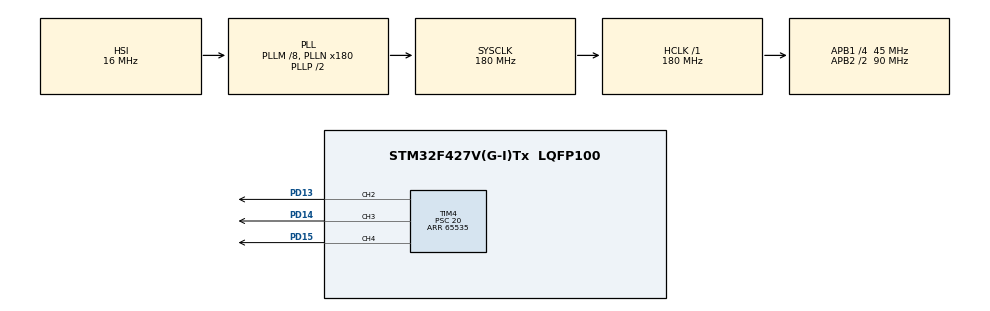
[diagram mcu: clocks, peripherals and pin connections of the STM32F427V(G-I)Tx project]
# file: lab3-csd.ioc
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Mcu.Family=STM32F4
Mcu.Name=STM32F427V(G-I)Tx
Mcu.Package=LQFP100
NVIC.PriorityGroup=NVIC_PRIORITYGROUP_4
NVIC.TIM6_DAC_IRQn=true\:0\:0\:false\:false\:true\:true\:true\:true
NVIC.TIM7_IRQn=true\:0\:0\:false\:false\:true\:true\:true\:true
PA13.Mode=JTAG_5_pins
PA13.Signal=SYS_JTMS-SWDIO
PA14.Mode=JTAG_5_pins
PA14.Signal=SYS_JTCK-SWCLK
PA15.Mode=JTAG_5_pins
PA15.Signal=SYS_JTDI
PB3.Mode=JTAG_5_pins
PB3.Signal=SYS_JTDO-SWO
PB4.Mode=JTAG_5_pins
PB4.Signal=SYS_JTRST
PD13.Signal=S_TIM4_CH2
PD14.Signal=S_TIM4_CH3
PD15.Signal=S_TIM4_CH4
ProjectManager.HeapSize=0x200
ProjectManager.StackSize=0x400
ProjectManager.TargetToolchain=STM32CubeIDE
RCC.48MHZClocksFreq_Value=90000000
RCC.AHBFreq_Value=180000000
RCC.APB1CLKDivider=RCC_HCLK_DIV4
RCC.APB1Freq_Value=45000000
RCC.APB1TimFreq_Value=90000000
RCC.APB2CLKDivider=RCC_HCLK_DIV2
RCC.APB2Freq_Value=90000000
RCC.APB2TimFreq_Value=180000000
RCC.CortexFreq_Value=180000000
RCC.HCLKFreq_Value=180000000
RCC.HSE_VALUE=25000000
RCC.HSI_VALUE=16000000
RCC.LSE_VALUE=32768
RCC.PLLM=8
RCC.PLLN=180
RCC.SYSCLKFreq_VALUE=180000000
RCC.SYSCLKSource=RCC_SYSCLKSOURCE_PLLCLK
RCC.VCOOutputFreq_Value=360000000
SH.S_TIM4_CH2.0=TIM4_CH2,PWM Generation2 CH2
SH.S_TIM4_CH3.0=TIM4_CH3,PWM Generation3 CH3
SH.S_TIM4_CH4.0=TIM4_CH4,PWM Generation4 CH4
TIM4.Channel-PWM\ Generation2\ CH2=TIM_CHANNEL_2
TIM4.Channel-PWM\ Generation3\ CH3=TIM_CHANNEL_3
TIM4.Channel-PWM\ Generation4\ CH4=TIM_CHANNEL_4
TIM4.Period=65535
TIM4.Prescaler=20
TIM4.Pulse-PWM\ Generation2\ CH2=500
TIM6.Period=65535
TIM6.Prescaler=8999
TIM7.Period=65535
TIM7.Prescaler=8999
VP_TIM4_VS_ClockSourceINT.Mode=Internal
VP_TIM6_VS_ClockSourceINT.Mode=Enable_Timer
VP_TIM7_VS_ClockSourceINT.Mode=Enable_Timer
board=custom

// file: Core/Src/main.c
/* USER CODE BEGIN Header */
/**
  ******************************************************************************
  * @file           : main.c
  * @brief          : Main program body
  ******************************************************************************
  * @attention
  *
  * Copyright (c) 2025 STMicroelectronics.
  * All rights reserved.
  *
  * This software is licensed under terms that can be found in the LICENSE file
  * in the root directory of this software component.
  * If no LICENSE file comes with this software, it is provided AS-IS.
  *
  ******************************************************************************
  */
/* USER CODE END Header */
#include "main.h"

TIM_HandleTypeDef htim4;
TIM_HandleTypeDef htim6;
TIM_HandleTypeDef htim7;

void SystemClock_Config(void);
static void MX_GPIO_Init(void);
static void MX_TIM4_Init(void);
static void MX_TIM6_Init(void);
static void MX_TIM7_Init(void);

/* USER CODE BEGIN 0 */

#define MAX_PHASE 10
#define GREEN 2
#define ORANGE 3
#define RED 4
#define MAX_BRIGHT 65536
#define MIN_BRIGHT 0
#define GREEN_TIMER &htim6
#define RED_ORANGE_TIMER &htim7
int start_timer_gr_val = 0;
int start_timer_ro_val = 0;
int max_green = MAX_BRIGHT;
int max_ro = MAX_BRIGHT;
int is_up_green_global = -1;
int is_up_ro_global = -1;

void change_speed(TIM_HandleTypeDef *timer, int speed) {
	__HAL_TIM_SET_PRESCALER(timer, speed);
}

int light_green(int speed, int max_brightness, int min_brightness, int is_up) {
	if(is_up_green_global == -1) is_up_green_global = is_up;
	change_speed(GREEN_TIMER, speed);
	int cur_ticks = __HAL_TIM_GET_COUNTER(GREEN_TIMER);
	int up_brightness = (cur_ticks > min_brightness ? (cur_ticks < max_brightness ? cur_ticks : max_brightness) : min_brightness);
	int less_brightness = (max_brightness-cur_ticks > min_brightness ? (max_brightness-cur_ticks) : min_brightness);
	int cur_brightness = is_up == 1 ? up_brightness : less_brightness;

	TIM4->CCR2=cur_brightness;

	if(is_up_green_global != is_up) {
		is_up_green_global = is_up;
		__HAL_TIM_SET_COUNTER(GREEN_TIMER, cur_ticks >= max_green ? min_brightness : cur_ticks);
	}

	max_green = max_brightness;
	return cur_ticks >= max_green ? 1 : 0;
}

int light_orange_red(int speed, int color, int max_brightness, int min_brightness, int is_up) {
	if(is_up_ro_global == -1) is_up_ro_global = is_up;
	change_speed(RED_ORANGE_TIMER, speed);
	int cur_ticks = __HAL_TIM_GET_COUNTER(RED_ORANGE_TIMER);
	int cur_brightness = is_up == 1 ? cur_ticks : MAX_BRIGHT - cur_ticks;

	if(color == ORANGE) TIM4->CCR3=cur_brightness;
	else if(color == RED) TIM4->CCR4=cur_brightness;

	if(is_up_ro_global != is_up) {
		is_up_ro_global = is_up;
		__HAL_TIM_SET_COUNTER(RED_ORANGE_TIMER, cur_ticks >= max_ro ? min_brightness : cur_ticks);
	}

	max_ro = max_brightness;
	return cur_ticks >= max_ro ? 1 : 0;
}

int light(int speed, int color, int min_brightness, int max_brightness, int is_up) {
	if(max_brightness > MAX_BRIGHT) max_brightness = MAX_BRIGHT;
	if(min_brightness < MIN_BRIGHT) min_brightness = MIN_BRIGHT;
	if(color == GREEN) return light_green(speed, max_brightness, min_brightness, is_up);
	else return light_orange_red(speed, color, max_brightness, min_brightness, is_up);
}

void HAL_TIM_PeriodElapsedCallback(TIM_HandleTypeDef *htim)
{
	if( htim->Instance == TIM6 ){
		__HAL_TIM_SET_COUNTER(GREEN_TIMER, max_green);
	}
	if( htim->Instance == TIM7 ){
		__HAL_TIM_SET_COUNTER(RED_ORANGE_TIMER, max_ro);
	}
}

/* USER CODE END 0 */

int main(void)
{

  /* MCU Configuration--------------------------------------------------------*/

  /* Reset of all peripherals, Initializes the Flash interface and the Systick. */
  HAL_Init();

  /* Configure the system clock */
  SystemClock_Config();

  /* Initialize all configured peripherals */
  MX_GPIO_Init();
  MX_TIM4_Init();
  MX_TIM6_Init();
  MX_TIM7_Init();

  /* Infinite loop */
  /* USER CODE BEGIN WHILE */
  HAL_TIM_Base_Start_IT(&htim6);
  HAL_TIM_Base_Start_IT(&htim7);
  HAL_TIM_PWM_Start(&htim4, TIM_CHANNEL_2);
  HAL_TIM_PWM_Start(&htim4, TIM_CHANNEL_3);
  HAL_TIM_PWM_Start(&htim4, TIM_CHANNEL_4);

  int up = 0;
  while (1)
  {
	  if(light(1000, RED, 0, 65535, up) == 1) {
		  up = 1;
	  }
//	  light(1000, GREEN, 0, 65535, 0);
    /* USER CODE END WHILE */

  }
}

void SystemClock_Config(void)
{
  RCC_OscInitTypeDef RCC_OscInitStruct = {0};
  RCC_ClkInitTypeDef RCC_ClkInitStruct = {0};

  /** Configure the main internal regulator output voltage
  */
  __HAL_RCC_PWR_CLK_ENABLE();
  __HAL_PWR_VOLTAGESCALING_CONFIG(PWR_REGULATOR_VOLTAGE_SCALE1);

  /** Initializes the RCC Oscillators according to the specified parameters
  * in the RCC_OscInitTypeDef structure.
  */
  RCC_OscInitStruct.OscillatorType = RCC_OSCILLATORTYPE_HSI;
  RCC_OscInitStruct.HSIState = RCC_HSI_ON;
  RCC_OscInitStruct.HSICalibrationValue = RCC_HSICALIBRATION_DEFAULT;
  RCC_OscInitStruct.PLL.PLLState = RCC_PLL_ON;
  RCC_OscInitStruct.PLL.PLLSource = RCC_PLLSOURCE_HSI;
  RCC_OscInitStruct.PLL.PLLM = 8;
  RCC_OscInitStruct.PLL.PLLN = 180;
  RCC_OscInitStruct.PLL.PLLP = RCC_PLLP_DIV2;
  RCC_OscInitStruct.PLL.PLLQ = 4;
  if (HAL_RCC_OscConfig(&RCC_OscInitStruct) != HAL_OK)
  {
    Error_Handler();
  }

  /** Activate the Over-Drive mode
  */
  if (HAL_PWREx_EnableOverDrive() != HAL_OK)
  {
    Error_Handler();
  }

  /** Initializes the CPU, AHB and APB buses clocks
  */
  RCC_ClkInitStruct.ClockType = RCC_CLOCKTYPE_HCLK|RCC_CLOCKTYPE_SYSCLK
                              |RCC_CLOCKTYPE_PCLK1|RCC_CLOCKTYPE_PCLK2;
  RCC_ClkInitStruct.SYSCLKSource = RCC_SYSCLKSOURCE_PLLCLK;
  RCC_ClkInitStruct.AHBCLKDivider = RCC_SYSCLK_DIV1;
  RCC_ClkInitStruct.APB1CLKDivider = RCC_HCLK_DIV4;
  RCC_ClkInitStruct.APB2CLKDivider = RCC_HCLK_DIV2;

  if (HAL_RCC_ClockConfig(&RCC_ClkInitStruct, FLASH_LATENCY_5) != HAL_OK)
  {
    Error_Handler();
  }
}

static void MX_TIM4_Init(void)
{

  TIM_ClockConfigTypeDef sClockSourceConfig = {0};
  TIM_MasterConfigTypeDef sMasterConfig = {0};
  TIM_OC_InitTypeDef sConfigOC = {0};

  htim4.Instance = TIM4;
  htim4.Init.Prescaler = 20;
  htim4.Init.CounterMode = TIM_COUNTERMODE_UP;
  htim4.Init.Period = 65535;
  htim4.Init.ClockDivision = TIM_CLOCKDIVISION_DIV1;
  htim4.Init.AutoReloadPreload = TIM_AUTORELOAD_PRELOAD_DISABLE;
  if (HAL_TIM_Base_Init(&htim4) != HAL_OK)
  {
    Error_Handler();
  }
  sClockSourceConfig.ClockSource = TIM_CLOCKSOURCE_INTERNAL;
  if (HAL_TIM_ConfigClockSource(&htim4, &sClockSourceConfig) != HAL_OK)
  {
    Error_Handler();
  }
  if (HAL_TIM_PWM_Init(&htim4) != HAL_OK)
  {
    Error_Handler();
  }
  sMasterConfig.MasterOutputTrigger = TIM_TRGO_RESET;
  sMasterConfig.MasterSlaveMode = TIM_MASTERSLAVEMODE_DISABLE;
  if (HAL_TIMEx_MasterConfigSynchronization(&htim4, &sMasterConfig) != HAL_OK)
  {
    Error_Handler();
  }
  sConfigOC.OCMode = TIM_OCMODE_PWM1;
  sConfigOC.Pulse = 500;
  sConfigOC.OCPolarity = TIM_OCPOLARITY_HIGH;
  sConfigOC.OCFastMode = TIM_OCFAST_DISABLE;
  if (HAL_TIM_PWM_ConfigChannel(&htim4, &sConfigOC, TIM_CHANNEL_2) != HAL_OK)
  {
    Error_Handler();
  }
  sConfigOC.Pulse = 0;
  if (HAL_TIM_PWM_ConfigChannel(&htim4, &sConfigOC, TIM_CHANNEL_3) != HAL_OK)
  {
    Error_Handler();
  }
  if (HAL_TIM_PWM_ConfigChannel(&htim4, &sConfigOC, TIM_CHANNEL_4) != HAL_OK)
  {
    Error_Handler();
  }
  HAL_TIM_MspPostInit(&htim4);

}

static void MX_TIM6_Init(void)
{

  TIM_MasterConfigTypeDef sMasterConfig = {0};

  htim6.Instance = TIM6;
  htim6.Init.Prescaler = 8999;
  htim6.Init.CounterMode = TIM_COUNTERMODE_UP;
  htim6.Init.Period = 65535;
  htim6.Init.AutoReloadPreload = TIM_AUTORELOAD_PRELOAD_DISABLE;
  if (HAL_TIM_Base_Init(&htim6) != HAL_OK)
  {
    Error_Handler();
  }
  sMasterConfig.MasterOutputTrigger = TIM_TRGO_RESET;
  sMasterConfig.MasterSlaveMode = TIM_MASTERSLAVEMODE_DISABLE;
  if (HAL_TIMEx_MasterConfigSynchronization(&htim6, &sMasterConfig) != HAL_OK)
  {
    Error_Handler();
  }

}

static void MX_TIM7_Init(void)
{

  TIM_MasterConfigTypeDef sMasterConfig = {0};

  htim7.Instance = TIM7;
  htim7.Init.Prescaler = 8999;
  htim7.Init.CounterMode = TIM_COUNTERMODE_UP;
  htim7.Init.Period = 65535;
  htim7.Init.AutoReloadPreload = TIM_AUTORELOAD_PRELOAD_DISABLE;
  if (HAL_TIM_Base_Init(&htim7) != HAL_OK)
  {
    Error_Handler();
  }
  sMasterConfig.MasterOutputTrigger = TIM_TRGO_RESET;
  sMasterConfig.MasterSlaveMode = TIM_MASTERSLAVEMODE_DISABLE;
  if (HAL_TIMEx_MasterConfigSynchronization(&htim7, &sMasterConfig) != HAL_OK)
  {
    Error_Handler();
  }

}

static void MX_GPIO_Init(void)
{

  /* GPIO Ports Clock Enable */
  __HAL_RCC_GPIOD_CLK_ENABLE();
  __HAL_RCC_GPIOA_CLK_ENABLE();
  __HAL_RCC_GPIOB_CLK_ENABLE();

}

void Error_Handler(void)
{
  __disable_irq();
  while (1)
  {
  }
}
